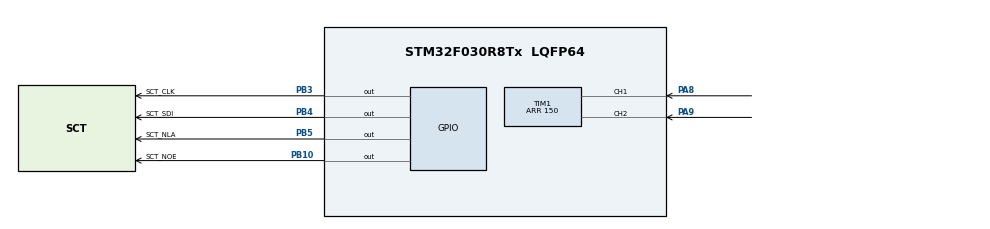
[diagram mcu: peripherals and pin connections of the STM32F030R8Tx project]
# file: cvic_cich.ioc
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Mcu.Family=STM32F0
Mcu.Name=STM32F030R8Tx
Mcu.Package=LQFP64
PA8.Signal=S_TIM1_CH1
PA9.Signal=S_TIM1_CH2
PB10.GPIO_Label=SCT_NOE
PB10.Signal=GPIO_Output
PB3.GPIO_Label=SCT_CLK
PB3.Signal=GPIO_Output
PB4.GPIO_Label=SCT_SDI
PB4.Signal=GPIO_Output
PB5.GPIO_Label=SCT_NLA
PB5.Signal=GPIO_Output
ProjectManager.HeapSize=0x200
ProjectManager.StackSize=0x400
ProjectManager.TargetToolchain=STM32CubeIDE
SH.S_TIM1_CH1.0=TIM1_CH1,Encoder_Interface
SH.S_TIM1_CH2.0=TIM1_CH2,Encoder_Interface
TIM1.IC1Polarity=TIM_ICPOLARITY_FALLING
TIM1.Period=150
board=custom

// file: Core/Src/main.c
/* USER CODE BEGIN Header */
/**
  ******************************************************************************
  * @file           : main.c
  * @brief          : Main program body
  ******************************************************************************
  * @attention
  *
  * <h2><center>&copy; Copyright (c) 2020 STMicroelectronics.
  * All rights reserved.</center></h2>
  *
  * This software component is licensed by ST under BSD 3-Clause license,
  * the "License"; You may not use this file except in compliance with the
  * License. You may obtain a copy of the License at:
  *                        opensource.org/licenses/BSD-3-Clause
  *
  ******************************************************************************
  */
/* USER CODE END Header */

#include "main.h"

/* USER CODE BEGIN Includes */
#include "LED_driver.h"

/* USER CODE END Includes */

TIM_HandleTypeDef htim1;

void SystemClock_Config(void);
static void MX_GPIO_Init(void);
static void MX_TIM1_Init(void);

int main(void)
{

  /* MCU Configuration--------------------------------------------------------*/

  /* Reset of all peripherals, Initializes the Flash interface and the Systick. */
  HAL_Init();

  /* Configure the system clock */
  SystemClock_Config();

  /* Initialize all configured peripherals */
  MX_GPIO_Init();
  MX_TIM1_Init();
  /* USER CODE BEGIN 2 */
  	  HAL_TIM_Encoder_Start(&htim1, htim1.Channel);
  	  HAL_Delay(1500);
  	  sct_init();
  	  sct_led(0x7A5C36DE);

  /* USER CODE END 2 */

  /* Infinite loop */
  while (1)
  {
	  /*for(int value = 0; value < 1000; value += 111) {
	  		sct_value(value);
	  		HAL_Delay(500);
	  }*/
	  sct_value(__HAL_TIM_GET_COUNTER(&htim1));
	  HAL_Delay(50);
  }
}

void SystemClock_Config(void)
{
  RCC_OscInitTypeDef RCC_OscInitStruct = {0};
  RCC_ClkInitTypeDef RCC_ClkInitStruct = {0};

  /** Initializes the CPU, AHB and APB busses clocks
  */
  RCC_OscInitStruct.OscillatorType = RCC_OSCILLATORTYPE_HSI;
  RCC_OscInitStruct.HSIState = RCC_HSI_ON;
  RCC_OscInitStruct.HSICalibrationValue = RCC_HSICALIBRATION_DEFAULT;
  RCC_OscInitStruct.PLL.PLLState = RCC_PLL_NONE;
  if (HAL_RCC_OscConfig(&RCC_OscInitStruct) != HAL_OK)
  {
    Error_Handler();
  }
  /** Initializes the CPU, AHB and APB busses clocks
  */
  RCC_ClkInitStruct.ClockType = RCC_CLOCKTYPE_HCLK|RCC_CLOCKTYPE_SYSCLK
                              |RCC_CLOCKTYPE_PCLK1;
  RCC_ClkInitStruct.SYSCLKSource = RCC_SYSCLKSOURCE_HSI;
  RCC_ClkInitStruct.AHBCLKDivider = RCC_SYSCLK_DIV1;
  RCC_ClkInitStruct.APB1CLKDivider = RCC_HCLK_DIV1;

  if (HAL_RCC_ClockConfig(&RCC_ClkInitStruct, FLASH_LATENCY_0) != HAL_OK)
  {
    Error_Handler();
  }
}

static void MX_TIM1_Init(void)
{

  TIM_Encoder_InitTypeDef sConfig = {0};
  TIM_MasterConfigTypeDef sMasterConfig = {0};

  htim1.Instance = TIM1;
  htim1.Init.Prescaler = 0;
  htim1.Init.CounterMode = TIM_COUNTERMODE_UP;
  htim1.Init.Period = 150;
  htim1.Init.ClockDivision = TIM_CLOCKDIVISION_DIV1;
  htim1.Init.RepetitionCounter = 0;
  htim1.Init.AutoReloadPreload = TIM_AUTORELOAD_PRELOAD_DISABLE;
  sConfig.EncoderMode = TIM_ENCODERMODE_TI1;
  sConfig.IC1Polarity = TIM_ICPOLARITY_FALLING;
  sConfig.IC1Selection = TIM_ICSELECTION_DIRECTTI;
  sConfig.IC1Prescaler = TIM_ICPSC_DIV1;
  sConfig.IC1Filter = 0;
  sConfig.IC2Polarity = TIM_ICPOLARITY_RISING;
  sConfig.IC2Selection = TIM_ICSELECTION_DIRECTTI;
  sConfig.IC2Prescaler = TIM_ICPSC_DIV1;
  sConfig.IC2Filter = 0;
  if (HAL_TIM_Encoder_Init(&htim1, &sConfig) != HAL_OK)
  {
    Error_Handler();
  }
  sMasterConfig.MasterOutputTrigger = TIM_TRGO_RESET;
  sMasterConfig.MasterSlaveMode = TIM_MASTERSLAVEMODE_DISABLE;
  if (HAL_TIMEx_MasterConfigSynchronization(&htim1, &sMasterConfig) != HAL_OK)
  {
    Error_Handler();
  }

}

static void MX_GPIO_Init(void)
{
  GPIO_InitTypeDef GPIO_InitStruct = {0};

  /* GPIO Ports Clock Enable */
  __HAL_RCC_GPIOB_CLK_ENABLE();
  __HAL_RCC_GPIOA_CLK_ENABLE();

  /*Configure GPIO pin Output Level */
  HAL_GPIO_WritePin(GPIOB, SCT_NOE_Pin|SCT_CLK_Pin|SCT_SDI_Pin|SCT_NLA_Pin, GPIO_PIN_RESET);

  /*Configure GPIO pins : SCT_NOE_Pin SCT_CLK_Pin SCT_SDI_Pin SCT_NLA_Pin */
  GPIO_InitStruct.Pin = SCT_NOE_Pin|SCT_CLK_Pin|SCT_SDI_Pin|SCT_NLA_Pin;
  GPIO_InitStruct.Mode = GPIO_MODE_OUTPUT_PP;
  GPIO_InitStruct.Pull = GPIO_NOPULL;
  GPIO_InitStruct.Speed = GPIO_SPEED_FREQ_LOW;
  HAL_GPIO_Init(GPIOB, &GPIO_InitStruct);

}

void Error_Handler(void)
{
}

/************************ (C) COPYRIGHT STMicroelectronics *****END OF FILE****/
